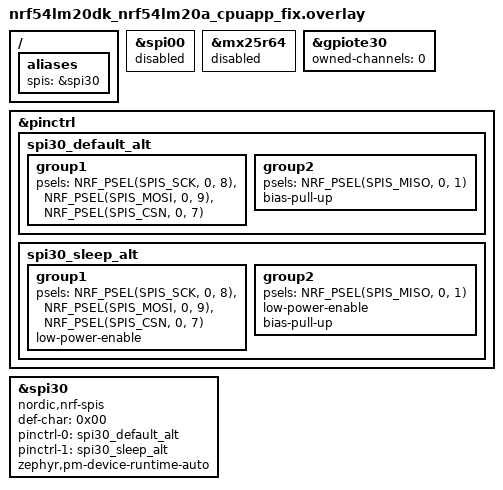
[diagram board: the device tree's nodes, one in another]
/*
 * Copyright (c) 2026 Nordic Semiconductor ASA
 *
 * SPDX-License-Identifier: LicenseRef-Nordic-5-Clause
 */

/ {
	aliases {
		spis = &spi30;
	};
};

/* Disable mx25r64. */
&spi00 {
	status = "disabled";
};

&mx25r64 {
	status = "disabled";
};

&gpiote30 {
	status = "okay";
	owned-channels = <0>;
};

&pinctrl {
	spi30_default_alt: spi30_default_alt {
		group1 {
			psels = <NRF_PSEL(SPIS_SCK, 0, 8)>,	/* UART0_RTS */
				<NRF_PSEL(SPIS_MOSI, 0, 9)>,	/* UART0_CTS */
				<NRF_PSEL(SPIS_CSN, 0, 7)>;	/* UART0_RX */
		};

		group2 {
			psels = <NRF_PSEL(SPIS_MISO, 0, 1)>;
			bias-pull-up;
		};
	};

	spi30_sleep_alt: spi30_sleep_alt {
		group1 {
			psels = <NRF_PSEL(SPIS_SCK, 0, 8)>,
				<NRF_PSEL(SPIS_MOSI, 0, 9)>,
				<NRF_PSEL(SPIS_CSN, 0, 7)>;
			low-power-enable;
		};

		group2 {
			psels = <NRF_PSEL(SPIS_MISO, 0, 1)>;
			low-power-enable;
			bias-pull-up;
		};
	};
};

&spi30 {
	compatible = "nordic,nrf-spis";
	status = "okay";
	def-char = <0x00>;
	pinctrl-0 = <&spi30_default_alt>;
	pinctrl-1 = <&spi30_sleep_alt>;
	pinctrl-names = "default", "sleep";
	/delete-property/ rx-delay-supported;
	/delete-property/ rx-delay;
	zephyr,pm-device-runtime-auto;
};
